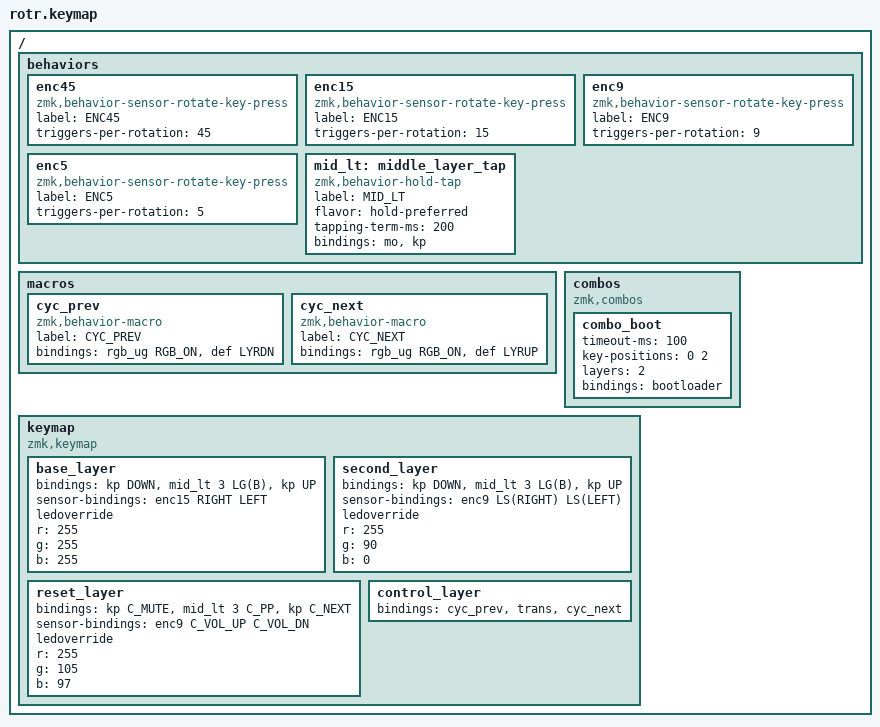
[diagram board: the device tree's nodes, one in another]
#include <behaviors.dtsi>
#include <dt-bindings/zmk/keys.h>
#include <dt-bindings/zmk/rgb.h>
#include <dt-bindings/zmk/default_layer.h>

/ {
	behaviors {
		/*
		 * The knob is a MagAlpha MA730 magnetic sensor (rotr.dts), not a
		 * detented EC11. resolution=8 deg/event gives 45 events per rotation,
		 * so 45 is the finest triggers-per-rotation; values should divide 45
		 * evenly (45/15/9/5/3) for even spacing. Higher = more sensitive.
		 */
		enc45: enc45 {
			compatible = "zmk,behavior-sensor-rotate-key-press";
			label = "ENC45";
			#sensor-binding-cells = <2>;
			triggers-per-rotation = <45>;
		};

		enc15: enc15 {
			compatible = "zmk,behavior-sensor-rotate-key-press";
			label = "ENC15";
			#sensor-binding-cells = <2>;
			triggers-per-rotation = <15>;
		};

		enc9: enc9 {
			compatible = "zmk,behavior-sensor-rotate-key-press";
			label = "ENC9";
			#sensor-binding-cells = <2>;
			triggers-per-rotation = <9>;
		};

		enc5: enc5 {
			compatible = "zmk,behavior-sensor-rotate-key-press";
			label = "ENC5";
			#sensor-binding-cells = <2>;
			triggers-per-rotation = <5>;
		};

		mid_lt: middle_layer_tap {
			compatible = "zmk,behavior-hold-tap";
			label = "MID_LT";
			flavor = "hold-preferred";
			tapping-term-ms = <200>;
			bindings = <&mo>, <&kp>;
			#binding-cells = <2>;
		};
	};

	macros {
		/*
		 * Cycle the default layer AND ensure the strip is on. RGB_ON persists
		 * on=true to NVS, but Zephyr NVS skips writes when the value is
		 * unchanged, so this only touches flash the first time. Per-layer color
		 * still comes from the ephemeral DEFAULTLAYER effect, not a saved color.
		 */
		cyc_prev: cyc_prev {
			compatible = "zmk,behavior-macro";
			label = "CYC_PREV";
			#binding-cells = <0>;
			bindings = <&rgb_ug RGB_ON>, <&def LYRDN>;
		};

		cyc_next: cyc_next {
			compatible = "zmk,behavior-macro";
			label = "CYC_NEXT";
			#binding-cells = <0>;
			bindings = <&rgb_ug RGB_ON>, <&def LYRUP>;
		};
	};

	combos {
		compatible = "zmk,combos";

		/* Bootloader = press both outer keys together, only on the reset layer. */
		combo_boot {
			timeout-ms = <100>;
			key-positions = <0 2>;
			layers = <2>;
			bindings = <&bootloader>;
		};
	};

	keymap {
		compatible = "zmk,keymap";

		/*
		 * Layers 0-2 are content layers cycled by &def (the fork's default-layer
		 * behavior). Their color comes from the DEFAULTLAYER underglow effect,
		 * which reads zmk_keymap_layer_default() and the ledoverride/r/g/b props
		 * below. Layer 3 is the control layer reached by holding the middle key.
		 */
		base_layer {
			bindings = <&kp DOWN &mid_lt 3 LG(B) &kp UP>;
			sensor-bindings = <&enc15 RIGHT LEFT>;
			/* white */
			ledoverride;
			r = <255>;
			g = <255>;
			b = <255>;
		};

		second_layer {
			bindings = <&kp DOWN &mid_lt 3 LG(B) &kp UP>;
			sensor-bindings = <&enc9 LS(RIGHT) LS(LEFT)>;
			/* orange */
			ledoverride;
			r = <255>;
			g = <90>;
			b = <0>;
		};

		reset_layer {
			/*
			 * Bootloader is the LEFT+RIGHT combo above, scoped to this layer, so it
			 * only fires on a deliberate two-key press. To leave without flashing,
			 * hold middle (control layer) and tap left/right to cycle away.
			 */
			bindings = <&kp C_MUTE &mid_lt 3 C_PP &kp C_NEXT>;
			sensor-bindings = <&enc9 C_VOL_UP C_VOL_DN>;
			/* pastel red (#FF6961) */
			ledoverride;
			r = <255>;
			g = <105>;
			b = <97>;
		};

		control_layer {
			/*
			 * Reached by holding the middle key. Tap left = previous layer,
			 * right = next layer, with wraparound. &def changes the default layer
			 * (re-rendering the LED) without deactivating this held layer, so you
			 * can keep middle held and tap repeatedly to cycle.
			 */
			bindings = <&cyc_prev &trans &cyc_next>;
		};
	};
};
